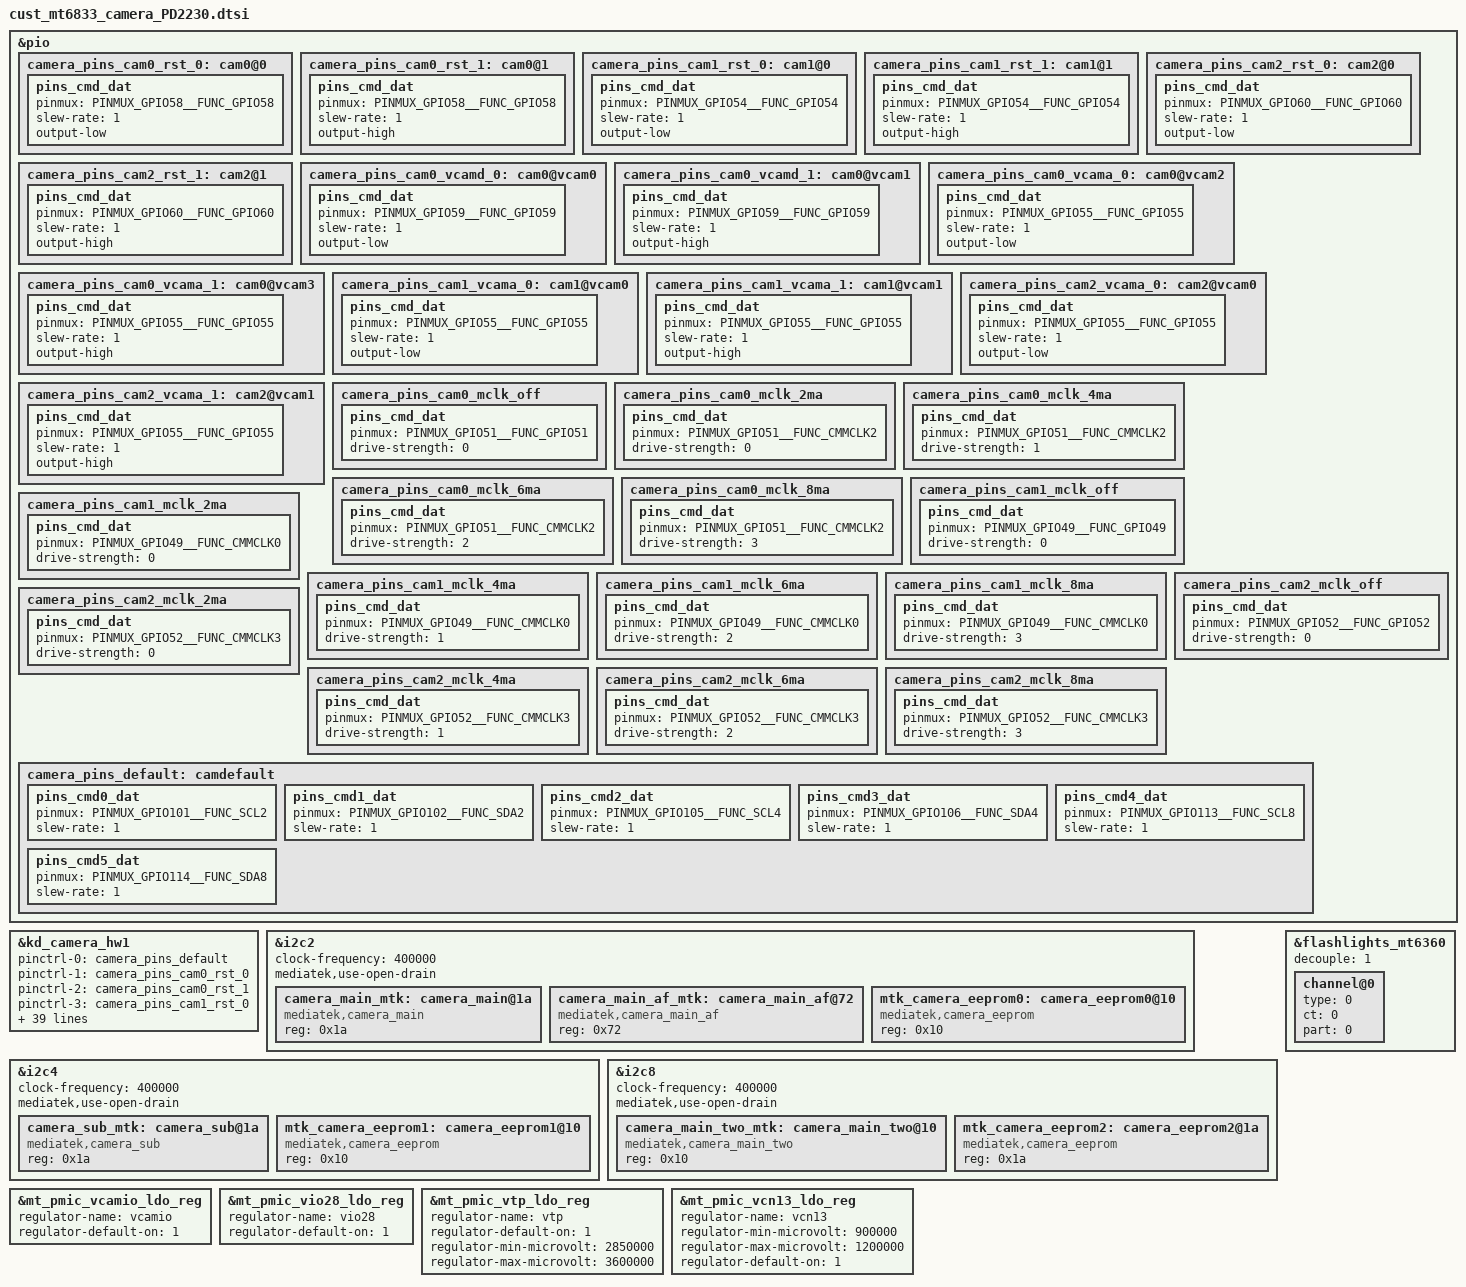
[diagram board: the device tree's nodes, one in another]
/* SPDX-License-Identifier: GPL-2.0 */
/*
 * Copyright (c) 2019 MediaTek Inc.
*/
/* CAMERA GPIO standardization */
&pio {
	camera_pins_cam0_rst_0: cam0@0 {
		pins_cmd_dat {
			pinmux = <PINMUX_GPIO58__FUNC_GPIO58>;
			slew-rate = <1>;
			output-low;
		};
	};
	camera_pins_cam0_rst_1: cam0@1 {
		pins_cmd_dat {
			pinmux = <PINMUX_GPIO58__FUNC_GPIO58>;
			slew-rate = <1>;
			output-high;
		};
	};

	camera_pins_cam1_rst_0: cam1@0 {
		pins_cmd_dat {
			pinmux = <PINMUX_GPIO54__FUNC_GPIO54>;
			slew-rate = <1>;
			output-low;
		};
	};
	camera_pins_cam1_rst_1: cam1@1 {
		pins_cmd_dat {
			pinmux = <PINMUX_GPIO54__FUNC_GPIO54>;
			slew-rate = <1>;
			output-high;
		};
	};

	camera_pins_cam2_rst_0: cam2@0 {
		pins_cmd_dat {
			pinmux = <PINMUX_GPIO60__FUNC_GPIO60>;
			slew-rate = <1>;
			output-low;
		};
	};
	camera_pins_cam2_rst_1: cam2@1 {
		pins_cmd_dat {
			pinmux = <PINMUX_GPIO60__FUNC_GPIO60>;
			slew-rate = <1>;
			output-high;
		};
	};

	/*main power start*/
	camera_pins_cam0_vcamd_0: cam0@vcam0 {
		pins_cmd_dat {
			pinmux = <PINMUX_GPIO59__FUNC_GPIO59>;
			slew-rate = <1>;
			output-low;
		};
	};
	camera_pins_cam0_vcamd_1: cam0@vcam1 {
		pins_cmd_dat {
			pinmux = <PINMUX_GPIO59__FUNC_GPIO59>;
			slew-rate = <1>;
			output-high;
		};
	};
	camera_pins_cam0_vcama_0: cam0@vcam2 {
		pins_cmd_dat {
			pinmux = <PINMUX_GPIO55__FUNC_GPIO55>;
			slew-rate = <1>;
			output-low;
		};
	};
	camera_pins_cam0_vcama_1: cam0@vcam3 {
		pins_cmd_dat {
			pinmux = <PINMUX_GPIO55__FUNC_GPIO55>;
			slew-rate = <1>;
			output-high;
		};
	};
	/*main power end*/
	/*sub power start*/
	camera_pins_cam1_vcama_0: cam1@vcam0 {
		pins_cmd_dat {
			pinmux = <PINMUX_GPIO55__FUNC_GPIO55>;
			slew-rate = <1>;
			output-low;
		};
	};
	camera_pins_cam1_vcama_1: cam1@vcam1 {
		pins_cmd_dat {
			pinmux = <PINMUX_GPIO55__FUNC_GPIO55>;
			slew-rate = <1>;
			output-high;
		};
	};
	/*sub power end*/

	/*macro power start*/
	camera_pins_cam2_vcama_0: cam2@vcam0 {
		pins_cmd_dat {
			pinmux = <PINMUX_GPIO55__FUNC_GPIO55>;
			slew-rate = <1>;
			output-low;
		};
	};
	camera_pins_cam2_vcama_1: cam2@vcam1 {
		pins_cmd_dat {
			pinmux = <PINMUX_GPIO55__FUNC_GPIO55>;
			slew-rate = <1>;
			output-high;
		};
	};
	/*macro power end*/

	camera_pins_cam0_mclk_off: camera_pins_cam0_mclk_off {
		pins_cmd_dat {
			pinmux = <PINMUX_GPIO51__FUNC_GPIO51>;
			drive-strength = <0>;
		};
	};
	camera_pins_cam0_mclk_2ma: camera_pins_cam0_mclk_2ma {
		pins_cmd_dat {
			pinmux = <PINMUX_GPIO51__FUNC_CMMCLK2>;
			drive-strength = <0>;
		};
	};
	camera_pins_cam0_mclk_4ma: camera_pins_cam0_mclk_4ma {
		pins_cmd_dat {
			pinmux = <PINMUX_GPIO51__FUNC_CMMCLK2>;
			drive-strength = <1>;
		};
	};
	camera_pins_cam0_mclk_6ma: camera_pins_cam0_mclk_6ma {
		pins_cmd_dat {
			pinmux = <PINMUX_GPIO51__FUNC_CMMCLK2>;
			drive-strength = <2>;
		};
	};
	camera_pins_cam0_mclk_8ma: camera_pins_cam0_mclk_8ma {
		pins_cmd_dat {
			pinmux = <PINMUX_GPIO51__FUNC_CMMCLK2>;
			drive-strength = <3>;
		};
	};

	camera_pins_cam1_mclk_off: camera_pins_cam1_mclk_off {
		pins_cmd_dat {
			pinmux = <PINMUX_GPIO49__FUNC_GPIO49>;
			drive-strength = <0>;
		};
	};
	camera_pins_cam1_mclk_2ma: camera_pins_cam1_mclk_2ma {
		pins_cmd_dat {
			pinmux = <PINMUX_GPIO49__FUNC_CMMCLK0>;
			drive-strength = <0>;
		};
	};
	camera_pins_cam1_mclk_4ma: camera_pins_cam1_mclk_4ma {
		pins_cmd_dat {
			pinmux = <PINMUX_GPIO49__FUNC_CMMCLK0>;
			drive-strength = <1>;
		};
	};
	camera_pins_cam1_mclk_6ma: camera_pins_cam1_mclk_6ma {
		pins_cmd_dat {
			pinmux = <PINMUX_GPIO49__FUNC_CMMCLK0>;
			drive-strength = <2>;
		};
	};
	camera_pins_cam1_mclk_8ma: camera_pins_cam1_mclk_8ma {
		pins_cmd_dat {
			pinmux = <PINMUX_GPIO49__FUNC_CMMCLK0>;
			drive-strength = <3>;
		};
	};

	camera_pins_cam2_mclk_off: camera_pins_cam2_mclk_off {
		pins_cmd_dat {
			pinmux = <PINMUX_GPIO52__FUNC_GPIO52>;
			drive-strength = <0>;
		};
	};
	camera_pins_cam2_mclk_2ma: camera_pins_cam2_mclk_2ma {
		pins_cmd_dat {
			pinmux = <PINMUX_GPIO52__FUNC_CMMCLK3>;
			drive-strength = <0>;
		};
	};
	camera_pins_cam2_mclk_4ma: camera_pins_cam2_mclk_4ma {
		pins_cmd_dat {
			pinmux = <PINMUX_GPIO52__FUNC_CMMCLK3>;
			drive-strength = <1>;
		};
	};
	camera_pins_cam2_mclk_6ma: camera_pins_cam2_mclk_6ma {
		pins_cmd_dat {
			pinmux = <PINMUX_GPIO52__FUNC_CMMCLK3>;
			drive-strength = <2>;
		};
	};
	camera_pins_cam2_mclk_8ma: camera_pins_cam2_mclk_8ma {
		pins_cmd_dat {
			pinmux = <PINMUX_GPIO52__FUNC_CMMCLK3>;
			drive-strength = <3>;
		};
	};

	camera_pins_default: camdefault {
		pins_cmd0_dat {
			pinmux = <PINMUX_GPIO101__FUNC_SCL2>;
			slew-rate = <1>;
		};
		pins_cmd1_dat {
			pinmux = <PINMUX_GPIO102__FUNC_SDA2>;
			slew-rate = <1>;
		};
		pins_cmd2_dat {
			pinmux = <PINMUX_GPIO105__FUNC_SCL4>;
			slew-rate = <1>;
		};
		pins_cmd3_dat {
			pinmux = <PINMUX_GPIO106__FUNC_SDA4 >;
			slew-rate = <1>;
		};
		pins_cmd4_dat {
			pinmux = <PINMUX_GPIO113__FUNC_SCL8>;
			slew-rate = <1>;
		};
		pins_cmd5_dat {
			pinmux = <PINMUX_GPIO114__FUNC_SDA8>;
			slew-rate = <1>;
		};
	};
};
&kd_camera_hw1 {
	pinctrl-names = "default",
		"cam0_rst0", "cam0_rst1",
		"cam1_rst0", "cam1_rst1",
		"cam2_rst0", "cam2_rst1",
		"cam0_ldo_vcamd_0", "cam0_ldo_vcamd_1",
		"cam0_ldo_vcama_0", "cam0_ldo_vcama_1",
		"cam1_ldo_vcama_0", "cam1_ldo_vcama_1",
		"cam2_ldo_vcama_0", "cam2_ldo_vcama_1",
		"cam0_mclk_off",
		"cam0_mclk_2mA", "cam0_mclk_4mA",
		"cam0_mclk_6mA", "cam0_mclk_8mA",
		"cam1_mclk_off",
		"cam1_mclk_2mA", "cam1_mclk_4mA",
		"cam1_mclk_6mA", "cam1_mclk_8mA",
		"cam2_mclk_off",
		"cam2_mclk_2mA", "cam2_mclk_4mA",
		"cam2_mclk_6mA", "cam2_mclk_8mA";

	pinctrl-0 = <&camera_pins_default>;
	pinctrl-1 = <&camera_pins_cam0_rst_0>;
	pinctrl-2 = <&camera_pins_cam0_rst_1>;
	pinctrl-3 = <&camera_pins_cam1_rst_0>;
	pinctrl-4 = <&camera_pins_cam1_rst_1>;
	pinctrl-5 = <&camera_pins_cam2_rst_0>;
	pinctrl-6 = <&camera_pins_cam2_rst_1>;
	pinctrl-7 = <&camera_pins_cam0_vcamd_0>;
	pinctrl-8 = <&camera_pins_cam0_vcamd_1>;
	pinctrl-9 = <&camera_pins_cam0_vcama_0>;
	pinctrl-10 = <&camera_pins_cam0_vcama_1>;
	pinctrl-11 = <&camera_pins_cam1_vcama_0>;
	pinctrl-12 = <&camera_pins_cam1_vcama_1>;
	pinctrl-13 = <&camera_pins_cam2_vcama_0>;
	pinctrl-14 = <&camera_pins_cam2_vcama_1>;
	pinctrl-15 = <&camera_pins_cam0_mclk_off>;
	pinctrl-16 = <&camera_pins_cam0_mclk_2ma>;
	pinctrl-17 = <&camera_pins_cam0_mclk_4ma>;
	pinctrl-18 = <&camera_pins_cam0_mclk_6ma>;
	pinctrl-19 = <&camera_pins_cam0_mclk_8ma>;
	pinctrl-20 = <&camera_pins_cam1_mclk_off>;
	pinctrl-21 = <&camera_pins_cam1_mclk_2ma>;
	pinctrl-22 = <&camera_pins_cam1_mclk_4ma>;
	pinctrl-23 = <&camera_pins_cam1_mclk_6ma>;
	pinctrl-24 = <&camera_pins_cam1_mclk_8ma>;
	pinctrl-25 = <&camera_pins_cam2_mclk_off>;
	pinctrl-26 = <&camera_pins_cam2_mclk_2ma>;
	pinctrl-27 = <&camera_pins_cam2_mclk_4ma>;
	pinctrl-28 = <&camera_pins_cam2_mclk_6ma>;
	pinctrl-29 = <&camera_pins_cam2_mclk_8ma>;

	gpio_nums = <6>;
	gpios = <101 102 105 106 113 114>;
	status = "okay";
};
/* CAMERA GPIO end */

/* GPS GPIO standardization end */

&i2c2 {
	#address-cells = <1>;
	#size-cells = <0>;
	clock-frequency = <400000>;
	mediatek,use-open-drain;
	camera_main_mtk:camera_main@1a {
		compatible = "mediatek,camera_main";
		reg = <0x1a>;
		status = "okay";
	};

	camera_main_af_mtk:camera_main_af@72 {
		compatible = "mediatek,camera_main_af";
		reg = <0x72>;
		status = "okay";
	};

	mtk_camera_eeprom0:camera_eeprom0@10 {
		compatible = "mediatek,camera_eeprom";
		reg = <0x10>;
		status = "okay";
	};
};

&i2c4 {
	#address-cells = <1>;
	#size-cells = <0>;
	clock-frequency = <400000>;
	mediatek,use-open-drain;
	camera_sub_mtk:camera_sub@1a {
		compatible = "mediatek,camera_sub";
		reg = <0x1a>;
		status = "okay";
	};

	mtk_camera_eeprom1:camera_eeprom1@10 {
		compatible = "mediatek,camera_eeprom";
		reg = <0x10>;
		status = "okay";
	};
};

&i2c8 {
	#address-cells = <1>;
	#size-cells = <0>;
	clock-frequency = <400000>;
	mediatek,use-open-drain;
	camera_main_two_mtk:camera_main_two@10 {
		compatible = "mediatek,camera_main_two";
		reg = <0x10>;
		status = "okay";
	};

	mtk_camera_eeprom2:camera_eeprom2@1a {
		compatible = "mediatek,camera_eeprom";
		reg = <0x1a>;
		status = "okay";
	};
};

/*************************
 * PMIC DTSI File
*************************/
&mt_pmic_vcamio_ldo_reg {
	regulator-name = "vcamio";
	regulator-default-on = <1>; /* 0:skip, 1: off, 2:on */
	status = "okay";
};
&mt_pmic_vio28_ldo_reg {
	regulator-name = "vio28";
	regulator-default-on = <1>; /* 0:skip, 1: off, 2:on */
	status = "okay";
};
&mt_pmic_vtp_ldo_reg {
	regulator-name = "vtp";
	regulator-default-on = <1>; /* 0:skip, 1: off, 2:on */
	regulator-min-microvolt = <2850000>;
	regulator-max-microvolt = <3600000>;
	status = "okay";
};

&mt_pmic_vcn13_ldo_reg{
	regulator-name = "vcn13";
	regulator-min-microvolt = <900000>;
	regulator-max-microvolt = <1200000>;
	regulator-default-on = <1>; /* 0:skip, 1: off, 2:on */
	status = "okay";
};
&kd_camera_hw1 {
	cam0_vcamio-supply = <&mt_pmic_vcamio_ldo_reg>;/*6365 vcamio*/
	cam1_vcamio-supply = <&mt_pmic_vcamio_ldo_reg>;
	cam2_vcamio-supply = <&mt_pmic_vcamio_ldo_reg>;
	cam0_vcamd1-supply = <&mt_pmic_vcn13_ldo_reg>;/*6365 DVDD*/
	cam1_vcamd-supply = <&mt_pmic_vcn13_ldo_reg>;/*6365 DVDD*/
	cam0_vcamaf_def-supply = <&mt_pmic_vio28_ldo_reg>;
	cam0_enable_sensor = "ov13b10pd2230_mipi_raw ov13b10v1pd2230_mipi_raw ov13b10v2pd2230_mipi_raw";
	cam1_enable_sensor = "s5k5e9pd2230_mipi_raw";
	cam2_enable_sensor = "gc02m1pd2230_mipi_raw ov02b10pd2230_mipi_raw";
	status = "okay";
};

&flashlights_mt6360 {
	decouple = <1>;
	channel@0 {
		type = <0>;
		ct = <0>;
		part = <0>;
	};
};
